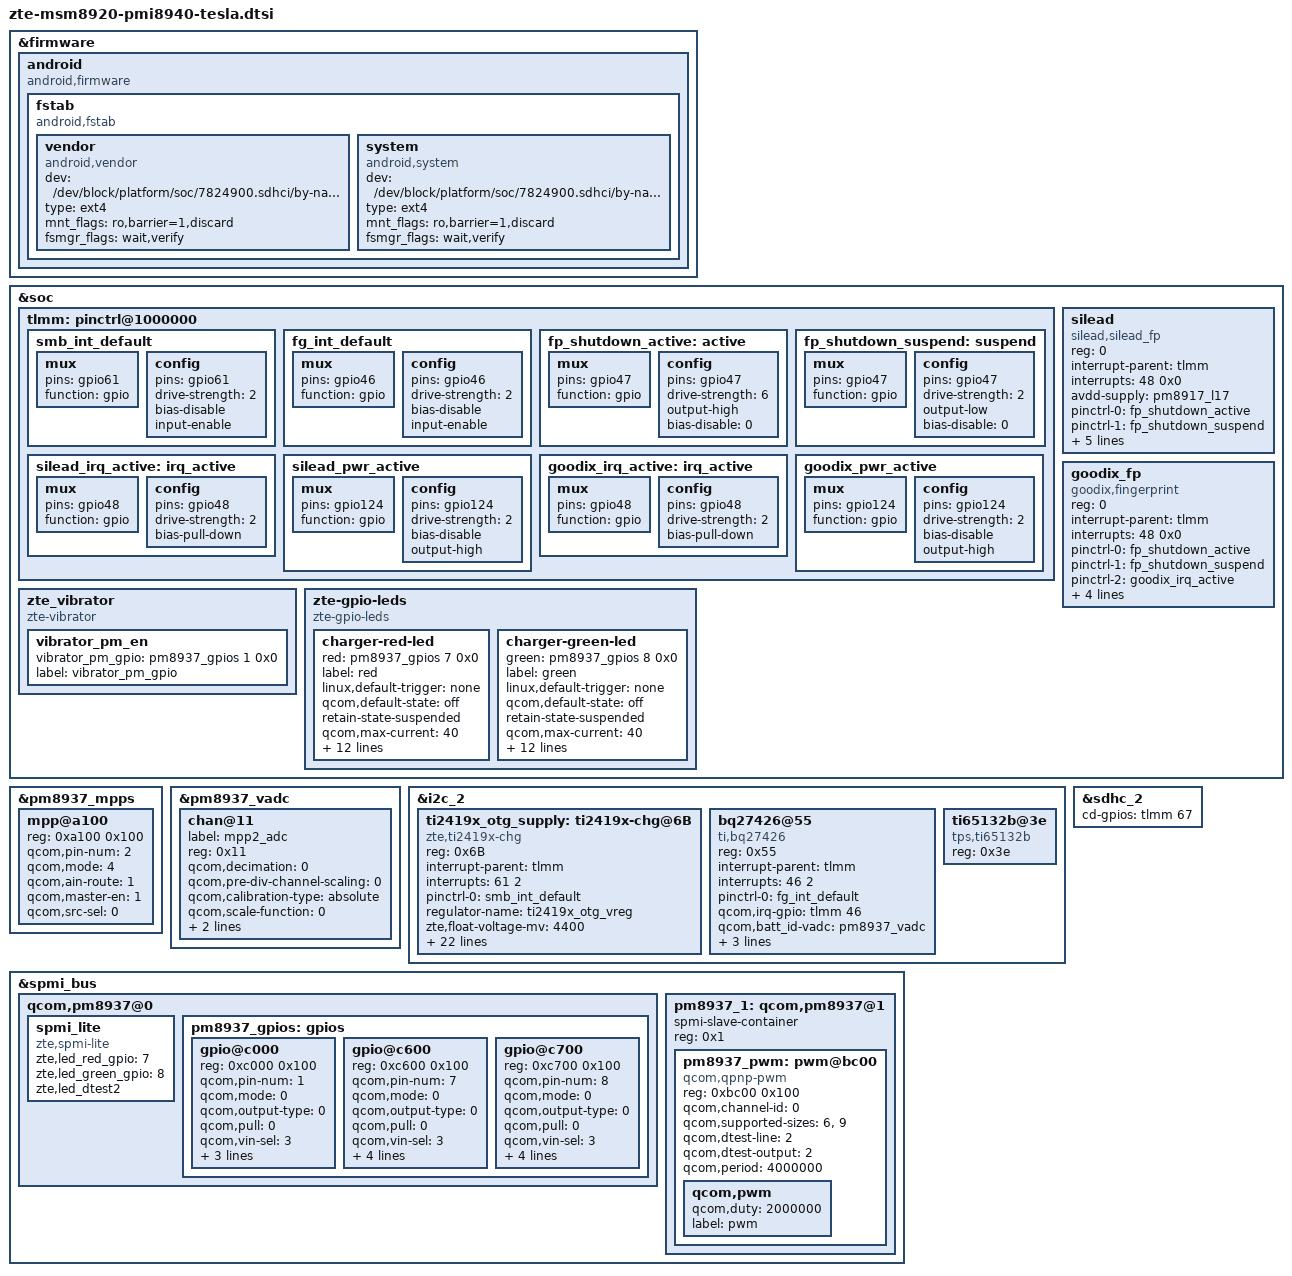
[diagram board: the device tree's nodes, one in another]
/*
 * device tree for zte tesla board
 */
&firmware {
		android {
			compatible = "android,firmware";
			fstab {
				compatible = "android,fstab";
				vendor {
					compatible = "android,vendor";
					dev = "/dev/block/platform/soc/7824900.sdhci/by-name/vendor";
					type = "ext4";
					mnt_flags = "ro,barrier=1,discard";
					fsmgr_flags = "wait,verify";
					status = "ok";
				};
				system {
					compatible = "android,system";
					dev = "/dev/block/platform/soc/7824900.sdhci/by-name/system";
					type = "ext4";
					mnt_flags = "ro,barrier=1,discard";
					fsmgr_flags = "wait,verify";
					status = "ok";
				};

			};
		};
	};

&soc {
	tlmm: pinctrl@1000000 {
		smb_int_default: smb_int_default {
			mux {
				pins = "gpio61";
				function = "gpio";
			};

			config {
				pins = "gpio61";
				drive-strength = <2>;
				bias-disable;
				input-enable;
			};
		};

		fg_int_default: fg_int_default {
			mux {
				pins = "gpio46";
				function = "gpio";
			};

			config {
				pins = "gpio46";
				drive-strength = <2>;
				bias-disable;
				input-enable;
			};
		};

		/* fpsilead */
		fp_shutdown_active:active{
				mux{
					pins = "gpio47";
					function = "gpio";
				};
				config{
					pins = "gpio47";
					drive-strength = <6>;
					output-high;
					bias-disable = <0>;
				};
		};
		fp_shutdown_suspend:suspend{
				mux{
					pins = "gpio47";
					function = "gpio";
				};
				config{
					pins = "gpio47";
					drive-strength = <2>;
					output-low;
					bias-disable = <0>;
				};
		};
		silead_irq_active:irq_active{
				mux{
					pins = "gpio48";
					function = "gpio";
				};
				config{
					pins = "gpio48";
					drive-strength = <2>;
					bias-pull-down;
				};
		};
		silead_pwr_active: silead_pwr_active {
				mux{
					pins = "gpio124";
					function = "gpio";
				};
				config {
					pins = "gpio124";
					drive-strength = <2>;
					bias-disable;
					output-high;
			};
		};
		//fpsilead end
		//goodix pinctrl begin
		goodix_irq_active:irq_active{
				mux{
					pins = "gpio48";
					function = "gpio";
				};
				config{
					pins = "gpio48";
					drive-strength = <2>;
					bias-pull-down;
				};
		};
		goodix_pwr_active: goodix_pwr_active {
				mux{
					pins = "gpio124";
					function = "gpio";
				};
				config {
					pins = "gpio124";
					drive-strength = <2>;
					bias-disable;
					output-high;
			};
		};
		// goodix pinctrl end
	};

	zte_vibrator {
		compatible = "zte-vibrator";
		vibrator_pm_en{
			vibrator_pm_gpio = <&pm8937_gpios 1 0x0>;
			label = "vibrator_pm_gpio";
		};
	};

	zte-gpio-leds {
		compatible = "zte-gpio-leds";
		charger-red-led {
			red = <&pm8937_gpios 7 0x0>;
			label = "red";
			linux,default-trigger = "none";
			qcom,default-state = "off";
			retain-state-suspended;
			qcom,max-current = <40>;
			qcom,current-setting = <5>;	/*+ zte add +*/
			qcom,source-sel = <8>;	/* connect GPIO to DTEST1 for PM8937 */
			qcom,mode-ctrl = <0x10>;	/* operation mode, default 0x60 = Mode Sink (org=0x10)*/
			qcom,pwm-channel = <0>;
			qcom,pwm-us = <1000>;
			qcom,vin-ctrl = <0x03>;		/* select input source, 0 to 3 */
			qcom,duty-pcts = <50>;
			qcom,mode = "pwm";
			qcom,use-blink;
			pwms = <&pm8937_pwm 0 0>;
			qcom,pwm-names = "red-led";
			zte,is-operator-sprint = "no";
		};
	};

	zte-gpio-leds {
		compatible = "zte-gpio-leds";
		charger-green-led {
			green = <&pm8937_gpios 8 0x0>;
			label = "green";
			linux,default-trigger = "none";
			qcom,default-state = "off";
			retain-state-suspended;
			qcom,max-current = <40>;
			qcom,current-setting = <5>;	/*+ zte add +*/
			qcom,source-sel = <8>;	/* connect GPIO to DTEST1 for PM8937 */
			qcom,mode-ctrl = <0x10>;	/* operation mode, default 0x60 = Mode Sink (org=0x10)*/
			qcom,pwm-channel = <0>;
			qcom,pwm-us = <1000>;
			qcom,vin-ctrl = <0x03>;		/* select input source, 0 to 3 */
			qcom,duty-pcts = <50>;
			qcom,mode = "pwm";
			qcom,use-blink;
			pwms = <&pm8937_pwm 0 0>;
			qcom,pwm-names = "green-led";
			zte,is-operator-sprint = "no";
		};
	};
	//silead
	silead {
		status = "ok";
		reg = <0>;
		compatible = "silead,silead_fp";
		interrupt-parent = <&tlmm>;
		interrupts = <48 0x0>;
		avdd-supply = <&pm8917_l17>;
		pinctrl-names = "silead_active", "silead_suspend", "silead_irq", "pwr_active";
		pinctrl-0 = <&fp_shutdown_active>;
		pinctrl-1 = <&fp_shutdown_suspend>;
		pinctrl-2 = <&silead_irq_active>;
		pinctrl-3 = <&silead_pwr_active>;

		silead,gpio_reset = <&tlmm 47 0>;
		silead,gpio_irq = <&tlmm 48 0>;
		silead,gpio_pwr = <&tlmm 124 0>;
		interrupt-names = "sl_wake_up";
	};
	goodix_fp {
		status = "ok";
		reg = <0>;
		compatible = "goodix,fingerprint";
		interrupt-parent = <&tlmm>;
		interrupts = <48 0x0>;

		pinctrl-names = "goodix_active", "goodix_suspend", "goodix_irq", "pwr_active";
		pinctrl-0 = <&fp_shutdown_active>;
		pinctrl-1 = <&fp_shutdown_suspend>;
		pinctrl-2 = <&goodix_irq_active>;
		pinctrl-3 = <&goodix_pwr_active>;

		fp-gpio-reset = <&tlmm 47 0>;
		fp-gpio-irq = <&tlmm 48 0>;
		/* goodix,gpio_pwr = <&tlmm 95 0>; */
		avdd-supply = <&pm8917_l17>;
		interrupt-names = "goodix_wake_up";
	};
};

&pm8937_mpps {
		mpp@a100 {
		/* MPP2 - BATT_ID config */
		reg = <0xa100 0x100>;
		qcom,pin-num = <2>;
		qcom,mode = <4>; /* AIN input */
		qcom,ain-route = <1>; /* AMUX 6 */
		qcom,master-en = <1>;
		qcom,src-sel = <0>; /* Function constant */
		/delete-property/qcom,invert;
		};
};

&pm8937_vadc {
		chan@11 {
		label = "mpp2_adc";
		reg = <0x11>;
		qcom,decimation = <0>;
		qcom,pre-div-channel-scaling = <0>;
		qcom,calibration-type = "absolute";
		qcom,scale-function = <0>;
		qcom,hw-settle-time = <1>;
		qcom,fast-avg-setup = <2>;
		/delete-property/qcom,vadc-thermal-node;
	};
};

&i2c_2 {
	ti2419x_otg_supply: ti2419x-chg@6B {
		compatible = "zte,ti2419x-chg";
		reg = <0x6B>;
		interrupt-parent = <&tlmm>;
		interrupts = <61 2>;
		pinctrl-names = "default";
		pinctrl-0 = <&smb_int_default>;
		regulator-name = "ti2419x_otg_vreg";

		zte,float-voltage-mv = <4400>;
		zte,iterm-ma = <150>;
		/*zte,hw-iterm-disabled;*/
		/*zte,charging-disabled; changed by zte */
		zte,recharge-thresh-mv = <100>;
		zte,warm_recharge-thresh-mv = <50>;
		zte,vbatdet-max-err-mv = <20>;
		zte,charging-timeout = <10>;
		zte,input_voltage_mv = <4520>;
		zte,max_usb_current = <3000>;
		zte,max_battery_current = <3000>;
		zte,thermal-mitigation = <2100 1500 900 500 0>;
		zte,warm_bat_mv = <4100>;
		zte,cool_bat_mv = <4400>;
		zte,warm-bat-decidegc = <440>;
		zte,cool-bat-decidegc = <100>;
		zte,cooler-bat-decidegc = <50>;
		zte,hot-bat-decidegc = <500>;
		zte,cold-bat-decidegc = <10>;
		zte,warm_bat_chg_ma = <1000>;
		zte,cool_bat_chg_ma = <1000>;
		zte,cooler_bat_chg_ma = <400>;
		qcom,tichg-vadc = <&pm8937_vadc>;
		zte,batt-hot-percentage = <20>; /*Only for k81:-5~49*/
		zte,batt-cold-percentage= <75>; /*Only for k81:-5~49*/
	};

	bq27426@55 {
		compatible = "ti,bq27426";
		reg = <0x55>;
		interrupt-parent = <&tlmm>;
		interrupts = <46 2>;
		pinctrl-names = "default";
		pinctrl-0 = <&fg_int_default>;
		qcom,irq-gpio = <&tlmm 46 0x0>;
		qcom,batt_id-vadc = <&pm8937_vadc>;
		qcom,batt-id-vref-uv = <1800000>;
		qcom,batt-id-rpullup-kohm = <10>;
		qcom,batt_full_design_capacity = <4000>;
	};

	ti65132b@3e {
		compatible = "tps,ti65132b";
		reg = <0x3e>;
	};
};

&spmi_bus {
	qcom,pm8937@0 {
		spmi_lite {
			compatible = "zte,spmi-lite";
			zte,led_red_gpio = <7>;
			zte,led_green_gpio = <8>;
			zte,led_dtest2;
		};

		pm8937_gpios: gpios {
			gpio@c000 {
				reg = <0xc000 0x100>;
				qcom,pin-num = <1>;
				qcom,mode = <0>;
				qcom,output-type = <0>;
				qcom,pull = <0>;
				qcom,vin-sel = <3>;
				qcom,out-strength = <3>;
				qcom,src-sel = <0>;
				qcom,master-en = <0>;
				//qcom,dtest-sel = <1>;
				status = "okay";
			};

			gpio@c600 {
				reg = <0xc600 0x100>;
				qcom,pin-num = <7>;
				qcom,mode = <0>;
				qcom,output-type = <0>;
				qcom,pull = <0>;
				qcom,vin-sel = <3>;
				qcom,out-strength = <3>;
				qcom,src-sel = <0>;
				qcom,master-en = <0>;
				qcom,dtest-sel = <0>;   /* This will set the offset 0x43 register */
				status = "okay";
			};

			gpio@c700 {
				reg = <0xc700 0x100>;
				qcom,pin-num = <8>;
				qcom,mode = <0>;
				qcom,output-type = <0>;
				qcom,pull = <0>;
				qcom,vin-sel = <3>;
				qcom,out-strength = <3>;
				qcom,src-sel = <0>;
				qcom,master-en = <0>;
				qcom,dtest-sel = <0>;
				status = "okay";
			};
		};
	};

	pm8937_1: qcom,pm8937@1 {
		spmi-slave-container;
		reg = <0x1>;
		#address-cells = <1>;
		#size-cells = <1>;

		pm8937_pwm: pwm@bc00 {
			status = "ok";
			compatible = "qcom,qpnp-pwm";
			reg = <0xbc00 0x100>;
			reg-names = "qpnp-lpg-channel-base";
			qcom,channel-id = <0>;
			qcom,supported-sizes = <6>, <9>;
			qcom,dtest-line = <2>;
			qcom,dtest-output = <2>;
			qcom,period = <4000000>;
			#pwm-cells = <2>;
			qcom,pwm {
				qcom,duty = <2000000>;
				label = "pwm";
			};
		};
	};
};
&sdhc_2 {
	cd-gpios = <&tlmm 67 0x0>;
};
